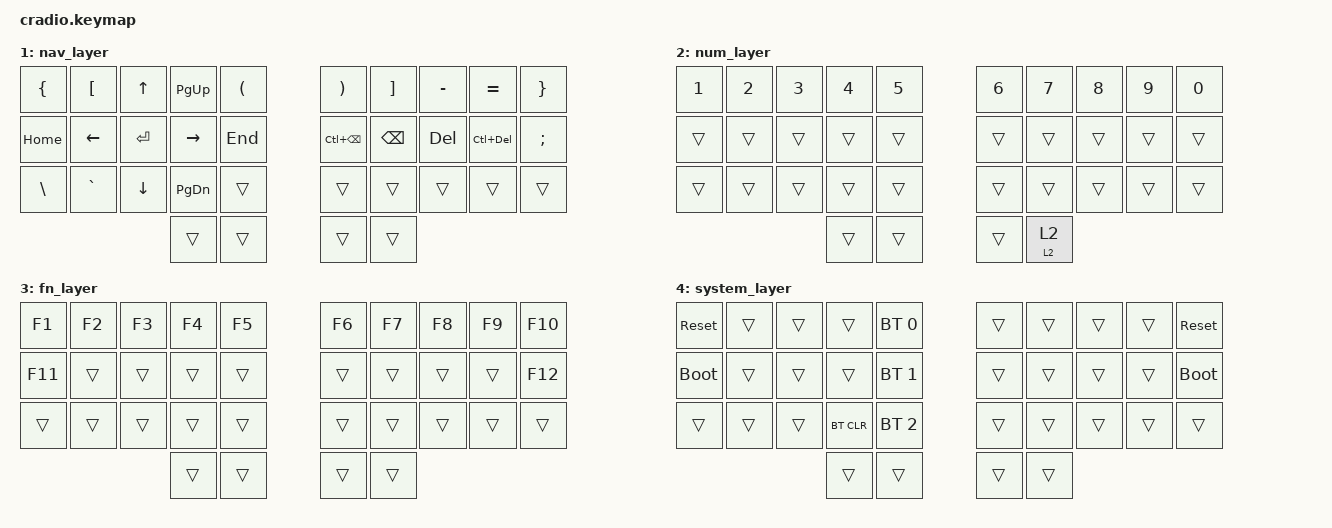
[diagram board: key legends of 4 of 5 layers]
// Copyright (c) 2022 The ZMK Contributors
// SPDX-License-Identifier: MIT

#include <behaviors.dtsi>
#include <dt-bindings/zmk/keys.h>
#include <dt-bindings/zmk/bt.h>

// Home row mods macro
#define HRML(k1,k2,k3,k4) &ht LSHFT k1  &ht LALT k2  &ht LCTRL k3  &ht LGUI k4
#define HRMR(k1,k2,k3,k4) &ht RGUI k1  &ht RCTRL k2  &ht RALT k3  &ht RSHFT k4

/ {
    behaviors {
        ht: hold_tap {
            compatible = "zmk,behavior-hold-tap";
            #binding-cells = <2>;
            flavor = "tap-preferred";
            tapping-term-ms = <220>;
            quick-tap-ms = <150>;
            require-prior-idle-ms = <100>;
            bindings = <&kp>, <&kp>;
        };

        ht_tog: hold_tap_toggle {
            compatible = "zmk,behavior-hold-tap";
            #binding-cells = <2>;
            flavor = "tap-preferred";
            tapping-term-ms = <220>;
            bindings = <&mo>, <&tog>;
        };

        td_q: tap_dance_q {
            compatible = "zmk,behavior-tap-dance";
            #binding-cells = <0>;
            tapping-term-ms = <200>;
            bindings = <&kp Q>, <&kp LA(F4)>;
        };

        td_w: tap_dance_w {
            compatible = "zmk,behavior-tap-dance";
            #binding-cells = <0>;
            tapping-term-ms = <200>;
            bindings = <&kp W>, <&kp CAPS>;
        };
    };

    combos {
        compatible = "zmk,combos";
        combo_numlock {
            timeout-ms = <50>;
            key-positions = <13 16>;
            bindings = <&kp KP_NLCK>;
        };

        combo_ctrl_tab {
            timeout-ms = <50>;
            key-positions = <2 3>;
            bindings = <&kp LC(TAB)>;
        };

        combo_ctrl_shift_tab {
            timeout-ms = <50>;
            key-positions = <6 7>;
            bindings = <&kp LC(LS(TAB))>;
        };
    };

    conditional_layers {
        compatible = "zmk,conditional-layers";
        system_layer {
            if-layers = <1 2>;
            then-layer = <4>;
        };
    };

    keymap {
        compatible = "zmk,keymap";
        default_layer {
            bindings = <
        //╭──────────┬──────────┬──────────┬──────────┬──────────╮   ╭──────────┬──────────┬──────────┬──────────┬──────────╮
        //│  Q       │  W       │  E       │  R       │  T       │   │  Y       │  U       │  I       │  O       │  P       │
            &td_q      &td_w      &kp E      &kp R      &kp T          &kp Y      &kp U      &kp I      &kp O      &kp P
        //├──────────┼──────────┼──────────┼──────────┼──────────┤   ├──────────┼──────────┼──────────┼──────────┼──────────┤
        //│  A       │  S       │  D       │  F       │  G       │   │  H       │  J       │  K       │  L       │ ' "      │
            HRML(A,        S,         D,         F)     &kp G          &kp H      HRMR(J,        K,         L,        SQT)
        //├──────────┼──────────┼──────────┼──────────┼──────────┤   ├──────────┼──────────┼──────────┼──────────┼──────────┤
        //│  Z       │  X       │  C       │  V       │  B       │   │  N       │  M       │ , <      │ . >      │ / ?      │
            &kp Z      &kp X      &kp C      &kp V      &kp B          &kp N      &kp M      &kp COMMA  &kp DOT    &kp FSLH
        //╰──────────┴──────────┴──────────┼──────────┼──────────┤   ├──────────┼──────────┼──────────┴──────────┴──────────╯
                                            &kp ESC    &lt 3 TAB      &lt 1 SPACE  &ht_tog 2 2
        //                                 ╰──────────┴──────────╯   ╰──────────┴──────────╯
            >;
        };

        nav_layer {
            bindings = <
        //╭──────────┬──────────┬──────────┬──────────┬──────────╮   ╭──────────┬──────────┬──────────┬──────────┬──────────╮
        //│  {       │  [       │  UP      │ PAGE UP  │  (       │   │  )       │  ]       │  -       │  =       │  }       │
            &kp LBRC   &kp LBKT   &kp UP     &kp PG_UP  &kp LPAR       &kp RPAR   &kp RBKT   &kp MINUS  &kp EQUAL  &kp RBRC
        //├──────────┼──────────┼──────────┼──────────┼──────────┤   ├──────────┼──────────┼──────────┼──────────┼──────────┤
        //│ HOME     │ LEFT     │ ENTER    │ RIGHT    │ END      │   │ C+BSPC   │ BSPC     │ DELETE   │ C+DEL    │  ; :     │
            &kp HOME   &kp LEFT   &kp ENTER  &kp RIGHT  &kp END        &kp LC(BSPC) &kp BSPC &kp DEL    &kp LC(DEL) &kp SEMI
        //├──────────┼──────────┼──────────┼──────────┼──────────┤   ├──────────┼──────────┼──────────┼──────────┼──────────┤
        //│  \ |     │  ` ~     │ DOWN     │ PAGE DN  │          │   │          │          │          │          │          │
            &kp BSLH   &kp GRAVE  &kp DOWN   &kp PG_DN  &trans         &trans     &trans     &trans     &trans     &trans
        //╰──────────┴──────────┴──────────┼──────────┼──────────┤   ├──────────┼──────────┼──────────┴──────────┴──────────╯
                                             &trans     &trans         &trans     &trans
        //                                 ╰──────────┴──────────╯   ╰──────────┴──────────╯
            >;
        };

        num_layer {
            bindings = <
        //╭──────────┬──────────┬──────────┬──────────┬──────────╮   ╭──────────┬──────────┬──────────┬──────────┬──────────╮
        //│  1       │  2       │  3       │  4       │  5       │   │  6       │  7       │  8       │  9       │  0       │
            &kp N1     &kp N2     &kp N3     &kp N4     &kp N5         &kp N6     &kp N7     &kp N8     &kp N9     &kp N0
        //├──────────┼──────────┼──────────┼──────────┼──────────┤   ├──────────┼──────────┼──────────┼──────────┼──────────┤
        //│          │          │          │          │          │   │          │          │          │          │          │
            &trans     &trans     &trans     &trans     &trans         &trans     &trans     &trans     &trans     &trans
        //├──────────┼──────────┼──────────┼──────────┼──────────┤   ├──────────┼──────────┼──────────┼──────────┼──────────┤
        //│          │          │          │          │          │   │          │          │          │          │          │
            &trans     &trans     &trans     &trans     &trans         &trans     &trans     &trans     &trans     &trans
        //╰──────────┴──────────┴──────────┼──────────┼──────────┤   ├──────────┼──────────┼──────────┴──────────┴──────────╯
                                             &trans     &trans         &trans     &ht_tog 2 2
        //                                 ╰──────────┴──────────╯   ╰──────────┴──────────╯
            >;
        };

        fn_layer {
            bindings = <
        //╭──────────┬──────────┬──────────┬──────────┬──────────╮   ╭──────────┬──────────┬──────────┬──────────┬──────────╮
        //│  F1      │  F2      │  F3      │  F4      │  F5      │   │  F6      │  F7      │  F8      │  F9      │  F10     │
            &kp F1     &kp F2     &kp F3     &kp F4     &kp F5         &kp F6     &kp F7     &kp F8     &kp F9     &kp F10
        //├──────────┼──────────┼──────────┼──────────┼──────────┤   ├──────────┼──────────┼──────────┼──────────┼──────────┤
        //│  F11     │          │          │          │          │   │          │          │          │          │  F12     │
            &kp F11    &trans     &trans     &trans     &trans         &trans     &trans     &trans     &trans     &kp F12
        //├──────────┼──────────┼──────────┼──────────┼──────────┤   ├──────────┼──────────┼──────────┼──────────┼──────────┤
        //│          │          │          │          │          │   │          │          │          │          │          │
            &trans     &trans     &trans     &trans     &trans         &trans     &trans     &trans     &trans     &trans
        //╰──────────┴──────────┴──────────┼──────────┼──────────┤   ├──────────┼──────────┼──────────┴──────────┴──────────╯
                                             &trans     &trans         &trans     &trans
        //                                 ╰──────────┴──────────╯   ╰──────────┴──────────╯
            >;
        };

        system_layer {
            bindings = <
        //╭──────────┬──────────┬──────────┬──────────┬──────────╮   ╭──────────┬──────────┬──────────┬──────────┬──────────╮
        //│ RESET    │          │          │          │PROFILE 0 │   │          │          │          │          │  RESET   │
           &sys_reset  &trans     &trans     &trans    &bt BT_SEL 0    &trans     &trans     &trans     &trans    &sys_reset
        //├──────────┼──────────┼──────────┼──────────┼──────────┤   ├──────────┼──────────┼──────────┼──────────┼──────────┤
        //│BOOTLOADER│          │          │          │PROFILE 1 │   │          │          │          │          │BOOTLOADER│
          &bootloader  &trans     &trans     &trans    &bt BT_SEL 1    &trans     &trans     &trans     &trans    &bootloader
        //├──────────┼──────────┼──────────┼──────────┼──────────┤   ├──────────┼──────────┼──────────┼──────────┼──────────┤
        //│          │          │          │ CLEAR BT │PROFILE 2 │   │          │          │          │          │          │
            &trans     &trans     &trans    &bt BT_CLR &bt BT_SEL 2    &trans     &trans     &trans     &trans     &trans
        //╰──────────┴──────────┴──────────┼──────────┼──────────┤   ├──────────┼──────────┼──────────┴──────────┴──────────╯
                                             &trans     &trans         &trans     &trans
        //                                 ╰──────────┴──────────╯   ╰──────────┴──────────╯
            >;
        };
    };
};
